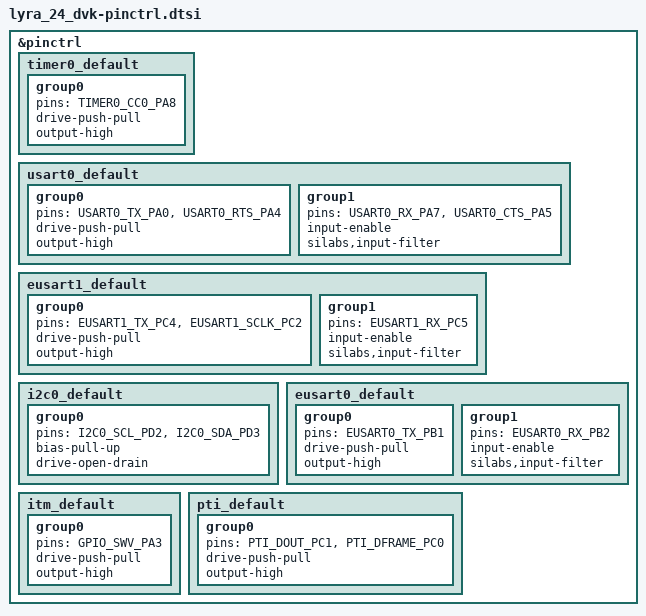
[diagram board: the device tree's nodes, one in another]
/*
 * Copyright (c) 2024 Silicon Laboratories Inc.
 * Copyright (c) 2026 Ezurio LLC
 *
 * SPDX-License-Identifier: Apache-2.0
 */

#include <zephyr/dt-bindings/pinctrl/silabs/xg24-pinctrl.h>

&pinctrl {
	timer0_default: timer0_default {
		group0 {
			pins = <TIMER0_CC0_PA8>;
			drive-push-pull;
			output-high;
		};
	};

	usart0_default: usart0_default {
		group0 {
			pins = <USART0_TX_PA0>, <USART0_RTS_PA4>;
			drive-push-pull;
			output-high;
		};

		group1 {
			pins = <USART0_RX_PA7>, <USART0_CTS_PA5>;
			input-enable;
			silabs,input-filter;
		};
	};

	eusart1_default: eusart1_default {
		group0 {
			pins = <EUSART1_TX_PC4>, <EUSART1_SCLK_PC2>;
			drive-push-pull;
			output-high;
		};

		group1 {
			pins = <EUSART1_RX_PC5>;
			input-enable;
			silabs,input-filter;
		};
	};

	i2c0_default: i2c0_default {
		group0 {
			pins = <I2C0_SCL_PD2>, <I2C0_SDA_PD3>;
			bias-pull-up;
			drive-open-drain;
		};
	};

	eusart0_default: eusart0_default {
		group0 {
			pins = <EUSART0_TX_PB1>;
			drive-push-pull;
			output-high;
		};

		group1 {
			pins = <EUSART0_RX_PB2>;
			input-enable;
			silabs,input-filter;
		};
	};

	itm_default: itm_default {
		group0 {
			pins = <GPIO_SWV_PA3>;
			drive-push-pull;
			output-high;
		};
	};

	pti_default: pti_default {
		group0 {
			pins = <PTI_DOUT_PC1>, <PTI_DFRAME_PC0>;
			drive-push-pull;
			output-high;
		};
	};
};
